AUTOSAR XML (schema 4-0-3)
package /ComponentTypes
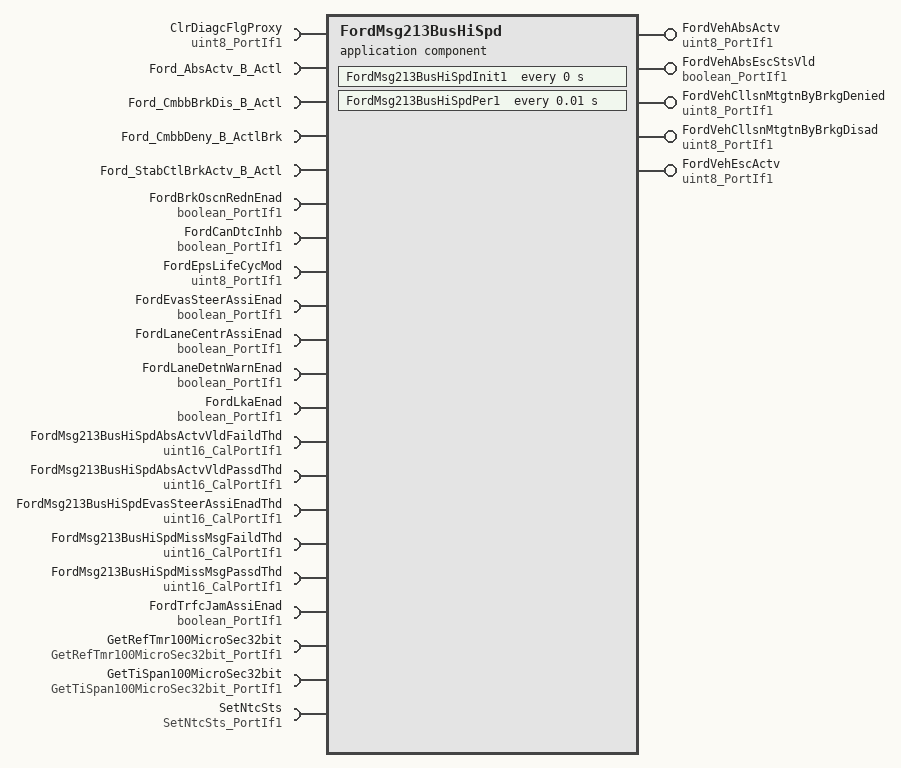
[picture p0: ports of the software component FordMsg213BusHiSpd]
  application sw component type FordMsg213BusHiSpd  # The purpose of the Ford Message 213 Bus High Speed function is to provide the Electric Power Steering system with signal values forthe Brake Oscillation Reduction, Lane Detection Warning, LKA, Traffic Jam Assist and Lane Center Assist functions from CAN.The FordMessage 213 function will perform the missing message and signal ivalid diagnostics as well as provide a validity flag for the signal values and received message
    5 x provide port:
      FordVehAbsActv: nonqueued-sender-com-spec{data-element=Val, init-value=0}, provided-interface=uint8_PortIf1  # Processed value of ABS Active to be used by EPS
      FordVehAbsEscStsVld: nonqueued-sender-com-spec{data-element=Logl, init-value=0}, provided-interface=boolean_PortIf1  # This output determines the validity of Ford Vehicle ABS ESC Status Val'id
      FordVehCllsnMtgtnByBrkgDenied: nonqueued-sender-com-spec{data-element=Val, init-value=0}, provided-interface=uint8_PortIf1  # Processed value of Collision Mitigation by Braking Rejected to be used by EPS
      FordVehCllsnMtgtnByBrkgDisad: nonqueued-sender-com-spec{data-element=Val, init-value=0}, provided-interface=uint8_PortIf1  # Processed value of Collision Mitigation by Braking Disabled to be used by EPS
      FordVehEscActv: nonqueued-sender-com-spec{data-element=Val, init-value=0}, provided-interface=uint8_PortIf1  # Processed value of ESC Active to be used by EPS
    21 x require port:
      ClrDiagcFlgProxy: nonqueued-receiver-com-spec{data-element=Val, filter=data-filter-type=ALWAYS, init-value=0}, required-interface=uint8_PortIf1  # When ClrDiagcFlgProxy is True, Diagnostic test is performed
      Ford_AbsActv_B_Actl: nonqueued-receiver-com-spec{data-element=Ford_AbsActv_B_Actl, filter=data-filter-type=ALWAYS, init-value=0}, required-interface=Ford_AbsActv_B_Actl  # It is a message signal which is received from CAN bus which will be processed and used in EPS. Datatype: Ford_AbsActv_B_Actl Elements are: 0 - "Cx0_No,1 - "Cx1_Yes
      Ford_CmbbBrkDis_B_Actl: nonqueued-receiver-com-spec{data-element=Ford_CmbbBrkDis_B_Actl, filter=data-filter-type=ALWAYS, init-value=0}, required-interface=Ford_CmbbBrkDis_B_Actl  # It is a message signal which is received from CAN bus which will be processed and used in EPS. Datatype: Ford_CmbbBrkDis_B_Actl Elements are: 0 - "Cx0_No,1 - "Cx1_Yes"
      Ford_CmbbDeny_B_ActlBrk: nonqueued-receiver-com-spec{data-element=Ford_CmbbDeny_B_ActlBrk, filter=data-filter-type=ALWAYS, init-value=0}, required-interface=Ford_CmbbDeny_B_ActlBrk  # It is a message signal which is received from CAN bus which will be processed and used in EPS. Datatype: Ford_CmbbDeny_B_ActlBrk Elements are: 0 - "Cx0_No,1 - "Cx1_Yes"
      Ford_StabCtlBrkActv_B_Actl: nonqueued-receiver-com-spec{data-element=Ford_StabCtlBrkActv_B_Actl, filter=data-filter-type=ALWAYS, init-value=0}, required-interface=Ford_StabCtlBrkActv_B_Actl  # It is a message signal which is received from CAN bus which will be processed and used in EPS. Datatype: Ford_StabCtlBrkActv_B_Actl Elements are: 0 - "Cx0_No,1 - "Cx1_Yes
      FordBrkOscnRednEnad: nonqueued-receiver-com-spec{data-element=Logl, filter=data-filter-type=ALWAYS, init-value=0}, required-interface=boolean_PortIf1  # This signal checks wheather Diagnostics needs to be performed or reset of timer and NTC is required. Customer datatype should be used. Data Type:Boolean with Min value "False"(0),Init value "False"(0) and Max value "True"(1)
      FordCanDtcInhb: nonqueued-receiver-com-spec{data-element=Logl, filter=data-filter-type=ALWAYS, init-value=1}, required-interface=boolean_PortIf1  # This signal should be set to 0 to enable the diagnostics. Customer datatype should be used. Data Type:Boolean with Min value "False"(0),Initvalue "False"(0) and Max value "True"(1)
      FordEpsLifeCycMod: nonqueued-receiver-com-spec{data-element=Val, filter=data-filter-type=ALWAYS, init-value=0}, required-interface=uint8_PortIf1  # This signal is used to decide time threshold value to FAIL the NTC
      FordEvasSteerAssiEnad: nonqueued-receiver-com-spec{data-element=Logl, filter=data-filter-type=ALWAYS, init-value=0}, required-interface=boolean_PortIf1  # This signal checks wheather Diagnostics needs to be performed or reset of timer and NTC is required. Customer datatype should be used. Data Type:Boolean with Min value "False"(0),Init value "False"(0) and Max value "True"(1)
      FordLaneCentrAssiEnad: nonqueued-receiver-com-spec{data-element=Logl, filter=data-filter-type=ALWAYS, init-value=0}, required-interface=boolean_PortIf1  # This signal checks wheather Diagnostics needs to be performed or reset of timer and NTC is required. Customer datatype should be used. Data Type:Boolean with Min value "False"(0),Init value "False"(0) and Max value "True"(1)
      FordLaneDetnWarnEnad: nonqueued-receiver-com-spec{data-element=Logl, filter=data-filter-type=ALWAYS, init-value=0}, required-interface=boolean_PortIf1  # This signal checks wheather Diagnostics needs to be performed or reset of timer and NTC is required. Customer datatype should be used. Data Type:Boolean with Min value "False"(0),Init value "False"(0) and Max value "True"(1)
      FordLkaEnad: nonqueued-receiver-com-spec{data-element=Logl, filter=data-filter-type=ALWAYS, init-value=0}, required-interface=boolean_PortIf1  # This signal checks wheather Diagnostics needs to be performed or reset of timer and NTC is required
      FordMsg213BusHiSpdAbsActvVldFaildThd: parameter-require-com-spec{init-value=200, parameter=Val}, required-interface=uint16_CalPortIf1  # Threshold to set the FordVehAbsEscStsVld to False
      FordMsg213BusHiSpdAbsActvVldPassdThd: parameter-require-com-spec{init-value=0, parameter=Val}, required-interface=uint16_CalPortIf1  # Threshold to set the FordVehAbsEscStsVld to True
      FordMsg213BusHiSpdEvasSteerAssiEnadThd: parameter-require-com-spec{init-value=200, parameter=Val}, required-interface=uint16_CalPortIf1  # Threshold to set the missing message NTC when EvasSteerAssiEnad is act'ive
      FordMsg213BusHiSpdMissMsgFaildThd: parameter-require-com-spec{init-value=5000, parameter=Val}, required-interface=uint16_CalPortIf1  # Threshold to set the missing message NTC
      FordMsg213BusHiSpdMissMsgPassdThd: parameter-require-com-spec{init-value=0, parameter=Val}, required-interface=uint16_CalPortIf1  # Threshold to clear the missing message NTC
      FordTrfcJamAssiEnad: nonqueued-receiver-com-spec{data-element=Logl, filter=data-filter-type=ALWAYS, init-value=0}, required-interface=boolean_PortIf1  # This signal checks wheather Diagnostics needs to be performed or reset of timer and NTC is required. Customer datatype should be used. Data Type:Boolean with Min value "False"(0),Init value "False"(0) and Max value "True"(1)
      GetRefTmr100MicroSec32bit: client-com-spec=Oper, required-interface=GetRefTmr100MicroSec32bit_PortIf1  # It captures simulation time fromthe SimnTi value obtained at root layer of model and gives the RefTmr
      GetTiSpan100MicroSec32bit: client-com-spec=Oper, required-interface=GetTiSpan100MicroSec32bit_PortIf1  # It Captures simulation time fromSimnTi value, handles counter wrapping, and subtracts RefTmr,provides the TiSpan
      SetNtcSts: client-com-spec=Oper, required-interface=SetNtcSts_PortIf1  # Set the NTC status
    behavior FordMsg213BusHiSpd_InternalBehavior
      ar-typed-per-instance-memorys:
        12 x data, all with sw-calibration-access=READ-ONLY:
          AbsActvVldFaildRefTi: type=uint32  # Holds the elapsed time before setting ABS Active Valid to Fail
          AbsActvVldPassdRefTi: type=uint32  # Holds the elapsed time before setting ABS Active Valid to Pass
          ClrDiagcFlgProxyPrev: type=uint8  # Clear Diagc Flag Proxy
          FirstTranVldFlg: type=boolean  # This flag is used to indicate the reception of first message
          FordVehAbsActvPrev: type=uint8  # Hold the Previous value of FordVehAbsActv
          FordVehAbsEscStsVldPrev: type=boolean  # Hold the Previous value of FordVehAbsEscStsVld
          FordVehCllsnMtgtnByBrkgDeniedPrev: type=uint8  # Hold the Previous value of FordVehCllsnMtgtnByBrkgDenied
          FordVehCllsnMtgtnByBrkgDisadPrev: type=uint8  # Hold the Previous value of FordVehCllsnMtgtnByBrkgDisad
          FordVehEscActvPrev: type=uint8  # Hold the Previous value of FordVehEscActv
          FordVehMsg213Miss: type=boolean  # Previous value of Ford Vehicle Message 213 Missing
          MissMsgFaildRefTi: type=uint32  # It holds the time to set miss message NTC to fail
          MissMsgPassdRefTi: type=uint32  # It holds the time to set miss message NTC to pass
      timing event FordMsg213BusHiSpd_InitEvent: start-on-event=FordMsg213BusHiSpdInit1, period=0
      timing event TMT_FordMsg213BusHiSpdPer1: start-on-event=FordMsg213BusHiSpdPer1, period=0.01
      runnable FordMsg213BusHiSpdInit1  # Initialization Runnable
        sync call SC_GetRefTmr100MicroSec32bit_Oper: operation=GetRefTmr100MicroSec32bit.Oper, timeout=0
      runnable FordMsg213BusHiSpdPer1  # Periodic Runnable at 10 milli-seconds
        data-receive-point-by-arguments:
          13 x access:
            REC_ClrDiagcFlgProxy_Val: accessed-variable=ClrDiagcFlgProxy.Val
            REC_Ford_AbsActv_B_Actl1_Ford_AbsActv_B_Actl: accessed-variable=Ford_AbsActv_B_Actl.Ford_AbsActv_B_Actl
            REC_Ford_CmbbBrkDis_B_Actl1_Ford_CmbbBrkDis_B_Actl: accessed-variable=Ford_CmbbBrkDis_B_Actl.Ford_CmbbBrkDis_B_Actl
            REC_Ford_CmbbDeny_B_ActlBrk1_Ford_CmbbDeny_B_ActlBrk: accessed-variable=Ford_CmbbDeny_B_ActlBrk.Ford_CmbbDeny_B_ActlBrk
            REC_Ford_StabCtlBrkActv_B_Actl_Ford_StabCtlBrkActv_B_Actl: accessed-variable=Ford_StabCtlBrkActv_B_Actl.Ford_StabCtlBrkActv_B_Actl
            REC_FordBrkOscnRednEnad_Logl: accessed-variable=FordBrkOscnRednEnad.Logl
            REC_FordCanDtcInhb_Logl: accessed-variable=FordCanDtcInhb.Logl
            REC_FordEpsLifeCycMod_Val: accessed-variable=FordEpsLifeCycMod.Val
            REC_FordEvasSteerAssiEnad_Logl: accessed-variable=FordEvasSteerAssiEnad.Logl
            REC_FordLaneCentrAssiEnad_Logl: accessed-variable=FordLaneCentrAssiEnad.Logl
            REC_FordLaneDetnWarnEnad_Logl: accessed-variable=FordLaneDetnWarnEnad.Logl
            REC_FordLkaEnad_Logl: accessed-variable=FordLkaEnad.Logl
            REC_FordTrfcJamAssiEnad_Logl: accessed-variable=FordTrfcJamAssiEnad.Logl
        data-send-points:
          5 x access:
            SEND_boolean_PortIf1_Logl: accessed-variable=FordVehAbsEscStsVld.Logl
            SEND_FordVehAbsActv_Val: accessed-variable=FordVehAbsActv.Val
            SEND_FordVehCllsnMtgtnByBrkgDenied_Val: accessed-variable=FordVehCllsnMtgtnByBrkgDenied.Val
            SEND_FordVehCllsnMtgtnByBrkgDisad_Val: accessed-variable=FordVehCllsnMtgtnByBrkgDisad.Val
            SEND_FordVehEscActv_Val: accessed-variable=FordVehEscActv.Val
        sync call SC_GetRefTmr100MicroSec32bit_Oper: operation=GetRefTmr100MicroSec32bit.Oper, timeout=0
        sync call SC_GetTiSpan100MicroSec32bit_Oper: operation=GetTiSpan100MicroSec32bit.Oper, timeout=0
        sync call SC_SetNtcSts_Oper: operation=SetNtcSts.Oper, timeout=0
  swc implementation FordMsg213BusHiSpd_Implementation: behavior=FordMsg213BusHiSpd_InternalBehavior
    code-descriptors:
      code Default: artifact-descriptors=autosar-engineering-object={short-label=Default, category=SWSRC}
